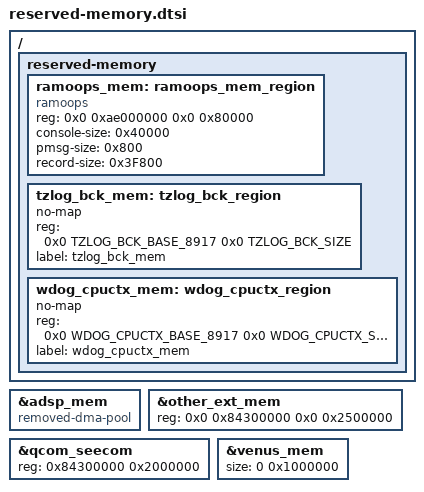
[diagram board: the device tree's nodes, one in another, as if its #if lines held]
#ifdef SOC_MSM8917
&adsp_mem {
	compatible = "removed-dma-pool";
};
#endif

&other_ext_mem {
	reg = <0x0 0x84300000 0x0 0x2500000>;
};

&qcom_seecom {
	reg = <0x84300000 0x2000000>;
};

&venus_mem {
	size = <0 0x1000000>;
};

/ {
	reserved-memory {
		ramoops_mem: ramoops_mem_region {
			compatible = "ramoops";
			reg = <0x0 0xae000000 0x0 0x80000>;
			console-size = <0x40000>;
			pmsg-size = <0x800>;
			record-size = <0x3F800>;
		};

		tzlog_bck_mem: tzlog_bck_region {
			no-map;
#ifdef SOC_MSM8917
			reg = <0x0 TZLOG_BCK_BASE_8917
				0x0 TZLOG_BCK_SIZE>;
#else
			reg = <0x0 TZLOG_BCK_BASE_8937
				0x0 TZLOG_BCK_SIZE>;
#endif
			label = "tzlog_bck_mem";
		};

		wdog_cpuctx_mem: wdog_cpuctx_region {
			no-map;
#ifdef SOC_MSM8917
			reg = <0x0 WDOG_CPUCTX_BASE_8917
				0x0 WDOG_CPUCTX_SIZE_8917>;
#else
			reg = <0x0 WDOG_CPUCTX_BASE_8937
				0x0 WDOG_CPUCTX_SIZE_8937>;
#endif
			label = "wdog_cpuctx_mem";
		};
	};
};
